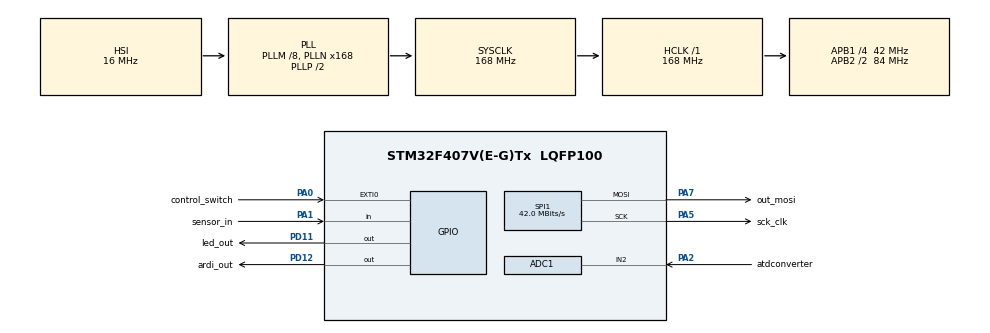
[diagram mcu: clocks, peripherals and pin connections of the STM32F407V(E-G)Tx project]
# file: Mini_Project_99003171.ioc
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ADC1.Channel-0\#ChannelRegularConversion=ADC_CHANNEL_2
ADC1.NbrOfConversionFlag=1
ADC1.Rank-0\#ChannelRegularConversion=1
ADC1.SamplingTime-0\#ChannelRegularConversion=ADC_SAMPLETIME_3CYCLES
ADC1.master=1
Mcu.Family=STM32F4
Mcu.Name=STM32F407V(E-G)Tx
Mcu.Package=LQFP100
NVIC.PriorityGroup=NVIC_PRIORITYGROUP_0
PA0-WKUP.GPIO_Label=control_switch
PA0-WKUP.Signal=GPXTI0
PA1.GPIO_Label=sensor_in
PA1.Signal=GPIO_Input
PA13.Mode=Serial_Wire
PA13.Signal=SYS_JTMS-SWDIO
PA14.Mode=Serial_Wire
PA14.Signal=SYS_JTCK-SWCLK
PA2.GPIO_Label=atdconverter
PA2.Signal=ADCx_IN2
PA5.GPIO_Label=sck_clk
PA5.Mode=TX_Only_Simplex_Unidirect_Master
PA5.Signal=SPI1_SCK
PA7.GPIO_Label=out_mosi
PA7.Mode=TX_Only_Simplex_Unidirect_Master
PA7.Signal=SPI1_MOSI
PD11.GPIO_Label=led_out
PD11.Signal=GPIO_Output
PD12.GPIO_Label=ardi_out
PD12.Signal=GPIO_Output
ProjectManager.HeapSize=0x200
ProjectManager.StackSize=0x400
ProjectManager.TargetToolchain=STM32CubeIDE
RCC.48MHZClocksFreq_Value=48000000
RCC.AHBFreq_Value=168000000
RCC.APB1CLKDivider=RCC_HCLK_DIV4
RCC.APB1Freq_Value=42000000
RCC.APB1TimFreq_Value=84000000
RCC.APB2CLKDivider=RCC_HCLK_DIV2
RCC.APB2Freq_Value=84000000
RCC.APB2TimFreq_Value=168000000
RCC.CortexFreq_Value=168000000
RCC.HCLKFreq_Value=168000000
RCC.HSE_VALUE=8000000
RCC.HSI_VALUE=16000000
RCC.PLLM=8
RCC.PLLN=168
RCC.PLLQ=7
RCC.SYSCLKFreq_VALUE=168000000
RCC.SYSCLKSource=RCC_SYSCLKSOURCE_PLLCLK
RCC.VCOOutputFreq_Value=336000000
SH.ADCx_IN2.0=ADC1_IN2,IN2
SPI1.CalculateBaudRate=42.0 MBits/s
SPI1.Direction=SPI_DIRECTION_2LINES
SPI1.Mode=SPI_MODE_MASTER
SPI1.VirtualType=VM_MASTER
board=STM32F407G-DISC1

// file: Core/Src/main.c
/* USER CODE BEGIN Header */
/**
  ******************************************************************************
  * @file           : main.c
  * @brief          : Main program body
  ******************************************************************************
  * @attention
  *
  * <h2><center>&copy; Copyright (c) 2021 STMicroelectronics.
  * All rights reserved.</center></h2>
  *
  * This software component is licensed by ST under Ultimate Liberty license
  * SLA0044, the "License"; You may not use this file except in compliance with
  * the License. You may obtain a copy of the License at:
  *                             www.st.com/SLA0044
  *
  ******************************************************************************
  */
/* USER CODE END Header */
#include "main.h"
#include<stdio.h>

ADC_HandleTypeDef haDc1;

SPI_HandleTypeDef hsPi1;

/* USER CODE BEGIN PV */
volatile uint8_t Flag_two=0;
/* USER CODE END PV */

void SystemClock_Config(void);
static void MX_GPIO_Init(void);
static void MX_SPI1_Init(void);
static void MX_ADC1_Init(void);

int main(void)
{
  /* USER CODE BEGIN 1 */
	volatile uint32_t ADC_VAL=0;
	volatile uint8_t Sensor_InPut1=0;
	uint8_t SpIDaTa1;
  /* USER CODE END 1 */

  /* MCU Configuration--------------------------------------------------------*/

  /* Reset of all peripherals, Initializes the Flash interface and the Systick. */
  HAL_Init();

  /* Configure the system clock */
  SystemClock_Config();

  /* Initialize all configured peripherals */
  MX_GPIO_Init();
  MX_SPI1_Init();
  MX_ADC1_Init();

  /* Infinite loop */
  /* USER CODE BEGIN WHILE */
  while (1)
  {
	  if (Flag_two == 1) //To check flag
	  	 	  {

	  	 	  HAL_GPIO_WritePin(led_out_GPIO_Port, led_out_Pin, Flag_two);
	  	 	  HAL_Delay(10);

	  	 	 Sensor_InPut1 = HAL_GPIO_ReadPin(sensor_in_GPIO_Port, sensor_in_Pin);
	  	 	  HAL_GPIO_WritePin(sensor_in_GPIO_Port, sensor_in_Pin, Sensor_InPut1);

	  	 	  HAL_ADC_Start(&haDc1);
	  	 	 	    	 if( HAL_ADC_PollForConversion(&haDc1, 5) == HAL_OK)
	  	 	 	    	 {
	  	 	 	    		ADC_VAL=HAL_ADC_GetValue(&haDc1);
	  	 	 	    	 }
	  	 	 	   HAL_Delay(50);
	  	 	 	 initialise_monitor_handles();

	  	 	 if(ADC_VAL>=512)
	  	 	 {
	  	 		 printf("analog value is greater than 512: value is %ld\n",ADC_VAL);
	  	 		SpIDaTa1=Sensor_InPut1;
	  	 		 printf("input sensor status : %d\n",Sensor_InPut1);

	  	 	 }
	  	 	 else
	  	 	 {
	  	 		printf("analog value is less than 512\n");
	  	 		SpIDaTa1=2;
	  	 	 }
	  	 	HAL_SPI_Transmit(&hsPi1, &SpIDaTa1, 1, 10);
	  	 	  }

	  	 else
	  	 	  {
	  	 		  HAL_GPIO_WritePin(led_out_GPIO_Port, led_out_Pin, Flag_two);
	  	 		  HAL_Delay(10);

	  		 	  HAL_GPIO_WritePin(sensor_in_GPIO_Port, sensor_in_Pin, 0);
	  	 	  }
  }
  /* USER CODE END 3 */
}

void SystemClock_Config(void)
{
  RCC_OscInitTypeDef RCC_OscInitStruct = {0};
  RCC_ClkInitTypeDef RCC_ClkInitStruct = {0};

  /** Configure the main internal regulator output voltage
  */
  __HAL_RCC_PWR_CLK_ENABLE();
  __HAL_PWR_VOLTAGESCALING_CONFIG(PWR_REGULATOR_VOLTAGE_SCALE1);
  /** Initializes the RCC Oscillators according to the specified parameters
  * in the RCC_OscInitTypeDef structure.
  */
  RCC_OscInitStruct.OscillatorType = RCC_OSCILLATORTYPE_HSI;
  RCC_OscInitStruct.HSIState = RCC_HSI_ON;
  RCC_OscInitStruct.HSICalibrationValue = RCC_HSICALIBRATION_DEFAULT;
  RCC_OscInitStruct.PLL.PLLState = RCC_PLL_ON;
  RCC_OscInitStruct.PLL.PLLSource = RCC_PLLSOURCE_HSI;
  RCC_OscInitStruct.PLL.PLLM = 8;
  RCC_OscInitStruct.PLL.PLLN = 168;
  RCC_OscInitStruct.PLL.PLLP = RCC_PLLP_DIV2;
  RCC_OscInitStruct.PLL.PLLQ = 7;
  if (HAL_RCC_OscConfig(&RCC_OscInitStruct) != HAL_OK)
  {
    Error_Handler();
  }
  /** Initializes the CPU, AHB and APB buses clocks
  */
  RCC_ClkInitStruct.ClockType = RCC_CLOCKTYPE_HCLK|RCC_CLOCKTYPE_SYSCLK
                              |RCC_CLOCKTYPE_PCLK1|RCC_CLOCKTYPE_PCLK2;
  RCC_ClkInitStruct.SYSCLKSource = RCC_SYSCLKSOURCE_PLLCLK;
  RCC_ClkInitStruct.AHBCLKDivider = RCC_SYSCLK_DIV1;
  RCC_ClkInitStruct.APB1CLKDivider = RCC_HCLK_DIV4;
  RCC_ClkInitStruct.APB2CLKDivider = RCC_HCLK_DIV2;

  if (HAL_RCC_ClockConfig(&RCC_ClkInitStruct, FLASH_LATENCY_5) != HAL_OK)
  {
    Error_Handler();
  }
}

static void MX_ADC1_Init(void)
{

  ADC_ChannelConfTypeDef sConfig = {0};

  /** Configure the global features of the ADC (Clock, Resolution, Data Alignment and number of conversion)
  */
  haDc1.Instance = ADC1;
  haDc1.Init.ClockPrescaler = ADC_CLOCK_SYNC_PCLK_DIV4;
  haDc1.Init.Resolution = ADC_RESOLUTION_12B;
  haDc1.Init.ScanConvMode = DISABLE;
  haDc1.Init.ContinuousConvMode = DISABLE;
  haDc1.Init.DiscontinuousConvMode = DISABLE;
  haDc1.Init.ExternalTrigConvEdge = ADC_EXTERNALTRIGCONVEDGE_NONE;
  haDc1.Init.ExternalTrigConv = ADC_SOFTWARE_START;
  haDc1.Init.DataAlign = ADC_DATAALIGN_RIGHT;
  haDc1.Init.NbrOfConversion = 1;
  haDc1.Init.DMAContinuousRequests = DISABLE;
  haDc1.Init.EOCSelection = ADC_EOC_SINGLE_CONV;
  if (HAL_ADC_Init(&haDc1) != HAL_OK)
  {
    Error_Handler();
  }
  /** Configure for the selected ADC regular channel its corresponding rank in the sequencer and its sample time.
  */
  sConfig.Channel = ADC_CHANNEL_2;
  sConfig.Rank = 1;
  sConfig.SamplingTime = ADC_SAMPLETIME_3CYCLES;
  if (HAL_ADC_ConfigChannel(&haDc1, &sConfig) != HAL_OK)
  {
    Error_Handler();
  }

}

static void MX_SPI1_Init(void)
{

  /* SPI1 parameter configuration*/
	hsPi1.Instance = SPI1;
	hsPi1.Init.Mode = SPI_MODE_MASTER;
	hsPi1.Init.Direction = SPI_DIRECTION_2LINES;
	hsPi1.Init.DataSize = SPI_DATASIZE_8BIT;
	hsPi1.Init.CLKPolarity = SPI_POLARITY_LOW;
	hsPi1.Init.CLKPhase = SPI_PHASE_1EDGE;
	hsPi1.Init.NSS = SPI_NSS_SOFT;
	hsPi1.Init.BaudRatePrescaler = SPI_BAUDRATEPRESCALER_2;
	hsPi1.Init.FirstBit = SPI_FIRSTBIT_MSB;
	hsPi1.Init.TIMode = SPI_TIMODE_DISABLE;
	hsPi1.Init.CRCCalculation = SPI_CRCCALCULATION_DISABLE;
	hsPi1.Init.CRCPolynomial = 10;
  if (HAL_SPI_Init(&hsPi1) != HAL_OK)
  {
    Error_Handler();
  }

}

static void MX_GPIO_Init(void)
{
  GPIO_InitTypeDef GPIO_InitStruct = {0};

  /* GPIO Ports Clock Enable */
  __HAL_RCC_GPIOA_CLK_ENABLE();
  __HAL_RCC_GPIOD_CLK_ENABLE();

  /*Configure GPIO pin Output Level */
  HAL_GPIO_WritePin(GPIOD, led_out_Pin|ardi_out_Pin, GPIO_PIN_RESET);

  /*Configure GPIO pin : control_switch_Pin */
  GPIO_InitStruct.Pin = control_switch_Pin;
  GPIO_InitStruct.Mode = GPIO_MODE_IT_RISING;
  GPIO_InitStruct.Pull = GPIO_NOPULL;
  HAL_GPIO_Init(control_switch_GPIO_Port, &GPIO_InitStruct);

  /*Configure GPIO pin : sensor_in_Pin */
  GPIO_InitStruct.Pin = sensor_in_Pin;
  GPIO_InitStruct.Mode = GPIO_MODE_INPUT;
  GPIO_InitStruct.Pull = GPIO_NOPULL;
  HAL_GPIO_Init(sensor_in_GPIO_Port, &GPIO_InitStruct);

  /*Configure GPIO pins : led_out_Pin ardi_out_Pin */
  GPIO_InitStruct.Pin = led_out_Pin|ardi_out_Pin;
  GPIO_InitStruct.Mode = GPIO_MODE_OUTPUT_PP;
  GPIO_InitStruct.Pull = GPIO_NOPULL;
  GPIO_InitStruct.Speed = GPIO_SPEED_FREQ_LOW;
  HAL_GPIO_Init(GPIOD, &GPIO_InitStruct);

}

void Error_Handler(void)
{
  __disable_irq();
  while (1)
  {
  }
}

/************************ (C) COPYRIGHT STMicroelectronics *****END OF FILE****/
